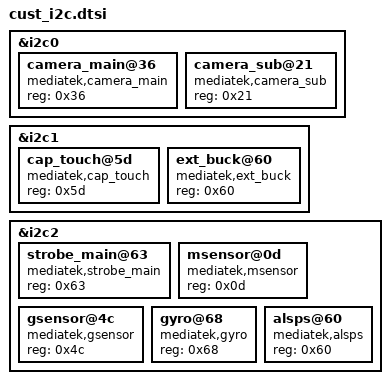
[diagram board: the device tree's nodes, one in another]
/*
 * Generated by MTK SP Drv_CodeGen Version 03.13.6	for MT6580. Copyright MediaTek Inc. (C) 2013.
 * Mon Feb 26 21:57:49 2024
 * Do Not Modify the File.
 */

/*************************
 * I2C DTSI File
*************************/

&i2c0 {
	#address-cells = <1>;
	#size-cells = <0>;
	camera_main@36 {
		compatible = "mediatek,camera_main";
		reg = <0x36>;
		status = "okay";
	};
	camera_sub@21 {
		compatible = "mediatek,camera_sub";
		reg = <0x21>;
		status = "okay";
	};
};

&i2c1 {
	#address-cells = <1>;
	#size-cells = <0>;
	cap_touch@5d {
		compatible = "mediatek,cap_touch";
		reg = <0x5d>;
		status = "okay";
	};
	ext_buck@60 {
		compatible = "mediatek,ext_buck";
		reg = <0x60>;
		status = "okay";
	};
};

&i2c2 {
	#address-cells = <1>;
	#size-cells = <0>;
	strobe_main@63 {
		compatible = "mediatek,strobe_main";
		reg = <0x63>;
		status = "okay";
	};
	msensor@0d {
		compatible = "mediatek,msensor";
		reg = <0x0d>;
		status = "okay";
	};
	gsensor@4c {
		compatible = "mediatek,gsensor";
		reg = <0x4c>;
		status = "okay";
	};
	gyro@68 {
		compatible = "mediatek,gyro";
		reg = <0x68>;
		status = "okay";
	};
	alsps@60 {
		compatible = "mediatek,alsps";
		reg = <0x60>;
		status = "okay";
	};
};

